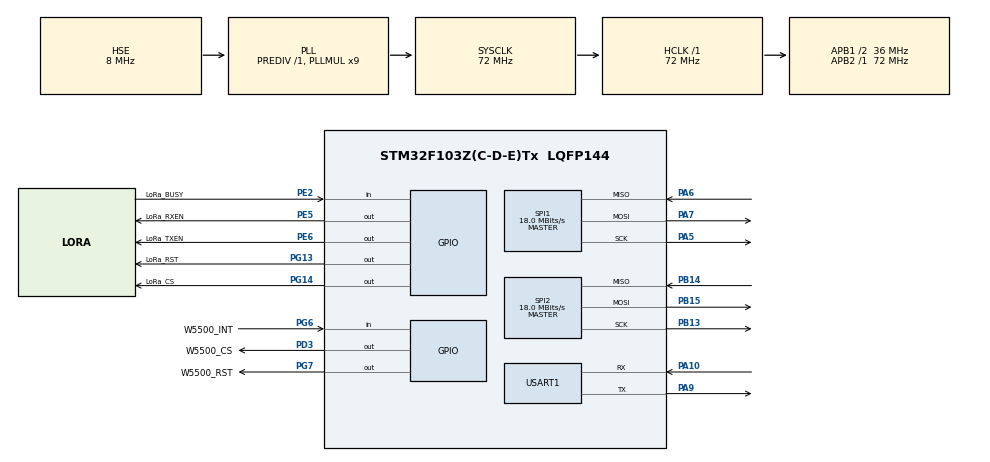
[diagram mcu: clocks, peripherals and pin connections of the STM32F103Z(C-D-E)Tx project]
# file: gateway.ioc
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Mcu.Family=STM32F1
Mcu.Name=STM32F103Z(C-D-E)Tx
Mcu.Package=LQFP144
NVIC.PriorityGroup=NVIC_PRIORITYGROUP_4
OSC_IN.Mode=HSE-External-Oscillator
OSC_IN.Signal=RCC_OSC_IN
OSC_OUT.Mode=HSE-External-Oscillator
OSC_OUT.Signal=RCC_OSC_OUT
PA10.Mode=Asynchronous
PA10.Signal=USART1_RX
PA13.Mode=Serial_Wire
PA13.Signal=SYS_JTMS-SWDIO
PA14.Mode=Serial_Wire
PA14.Signal=SYS_JTCK-SWCLK
PA5.Mode=Full_Duplex_Master
PA5.Signal=SPI1_SCK
PA6.Mode=Full_Duplex_Master
PA6.Signal=SPI1_MISO
PA7.Mode=Full_Duplex_Master
PA7.Signal=SPI1_MOSI
PA9.Mode=Asynchronous
PA9.Signal=USART1_TX
PB13.Mode=Full_Duplex_Master
PB13.Signal=SPI2_SCK
PB14.Mode=Full_Duplex_Master
PB14.Signal=SPI2_MISO
PB15.Mode=Full_Duplex_Master
PB15.Signal=SPI2_MOSI
PC14-OSC32_IN.Mode=LSE-External-Oscillator
PC14-OSC32_IN.Signal=RCC_OSC32_IN
PC15-OSC32_OUT.Mode=LSE-External-Oscillator
PC15-OSC32_OUT.Signal=RCC_OSC32_OUT
PD3.GPIO_Label=W5500_CS
PD3.PinState=GPIO_PIN_SET
PD3.Signal=GPIO_Output
PE2.GPIO_Label=LoRa_BUSY
PE2.Signal=GPIO_Input
PE5.GPIO_Label=LoRa_RXEN
PE5.Signal=GPIO_Output
PE6.GPIO_Label=LoRa_TXEN
PE6.Signal=GPIO_Output
PG13.GPIO_Label=LoRa_RST
PG13.PinState=GPIO_PIN_SET
PG13.Signal=GPIO_Output
PG14.GPIO_Label=LoRa_CS
PG14.PinState=GPIO_PIN_SET
PG14.Signal=GPIO_Output
PG6.GPIO_Label=W5500_INT
PG6.Signal=GPIO_Input
PG7.GPIO_Label=W5500_RST
PG7.PinState=GPIO_PIN_SET
PG7.Signal=GPIO_Output
ProjectManager.HeapSize=0x200
ProjectManager.StackSize=0x400
ProjectManager.TargetToolchain=MDK-ARM V5.32
RCC.AHBFreq_Value=72000000
RCC.APB1CLKDivider=RCC_HCLK_DIV2
RCC.APB1Freq_Value=36000000
RCC.APB1TimFreq_Value=72000000
RCC.APB2Freq_Value=72000000
RCC.APB2TimFreq_Value=72000000
RCC.HCLKFreq_Value=72000000
RCC.PLLMUL=RCC_PLL_MUL9
RCC.PLLSourceVirtual=RCC_PLLSOURCE_HSE
RCC.SYSCLKFreq_VALUE=72000000
RCC.SYSCLKSource=RCC_SYSCLKSOURCE_PLLCLK
RCC.USBFreq_Value=72000000
SPI1.BaudRatePrescaler=SPI_BAUDRATEPRESCALER_4
SPI1.CalculateBaudRate=18.0 MBits/s
SPI1.Direction=SPI_DIRECTION_2LINES
SPI1.Mode=SPI_MODE_MASTER
SPI1.VirtualType=VM_MASTER
SPI2.CalculateBaudRate=18.0 MBits/s
SPI2.Direction=SPI_DIRECTION_2LINES
SPI2.Mode=SPI_MODE_MASTER
SPI2.VirtualType=VM_MASTER
USART1.VirtualMode=VM_ASYNC
board=custom

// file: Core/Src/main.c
/* USER CODE BEGIN Header */
/**
 ******************************************************************************
 * @file           : main.c
 * @brief          : Main program body
 ******************************************************************************
 * @attention
 *
 * Copyright (c) 2026 STMicroelectronics.
 * All rights reserved.
 *
 * This software is licensed under terms that can be found in the LICENSE file
 * in the root directory of this software component.
 * If no LICENSE file comes with this software, it is provided AS-IS.
 *
 ******************************************************************************
 */
/* USER CODE END Header */
#include "main.h"
#include "spi.h"
#include "usart.h"
#include "gpio.h"

/* USER CODE BEGIN Includes */
#include "Com_Debug.h"
#include "Int_Lora.h"
#include "Com_Delay.h"
#include "Int_w5500.h"
/* USER CODE END Includes */

void SystemClock_Config(void);

int main(void)
{

  /* MCU Configuration--------------------------------------------------------*/

  /* Reset of all peripherals, Initializes the Flash interface and the Systick. */
  HAL_Init();

  /* Configure the system clock */
  SystemClock_Config();

  /* Initialize all configured peripherals */
  MX_GPIO_Init();
  MX_USART1_UART_Init();
  MX_SPI1_Init();
  MX_SPI2_Init();
  /* USER CODE BEGIN 2 */
  COM_DEBUG_LN("gateway start");
  // lora初始化
  Int_LoRa_Init();

  // w5500初始化,让w5500加入到局域网下
  Int_W5500_Init();

  /* USER CODE END 2 */

  /* Infinite loop */
  while (1)
  {

    /* USER CODE BEGIN 3 */
    // lora接受数据
    Int_Lora_Receive();
    Com_Delay_Sec(1);
  }
  /* USER CODE END 3 */
}

void SystemClock_Config(void)
{
  RCC_OscInitTypeDef RCC_OscInitStruct = {0};
  RCC_ClkInitTypeDef RCC_ClkInitStruct = {0};

  /** Initializes the RCC Oscillators according to the specified parameters
   * in the RCC_OscInitTypeDef structure.
   */
  RCC_OscInitStruct.OscillatorType = RCC_OSCILLATORTYPE_HSE;
  RCC_OscInitStruct.HSEState = RCC_HSE_ON;
  RCC_OscInitStruct.HSEPredivValue = RCC_HSE_PREDIV_DIV1;
  RCC_OscInitStruct.HSIState = RCC_HSI_ON;
  RCC_OscInitStruct.PLL.PLLState = RCC_PLL_ON;
  RCC_OscInitStruct.PLL.PLLSource = RCC_PLLSOURCE_HSE;
  RCC_OscInitStruct.PLL.PLLMUL = RCC_PLL_MUL9;
  if (HAL_RCC_OscConfig(&RCC_OscInitStruct) != HAL_OK)
  {
    Error_Handler();
  }

  /** Initializes the CPU, AHB and APB buses clocks
   */
  RCC_ClkInitStruct.ClockType = RCC_CLOCKTYPE_HCLK | RCC_CLOCKTYPE_SYSCLK | RCC_CLOCKTYPE_PCLK1 | RCC_CLOCKTYPE_PCLK2;
  RCC_ClkInitStruct.SYSCLKSource = RCC_SYSCLKSOURCE_PLLCLK;
  RCC_ClkInitStruct.AHBCLKDivider = RCC_SYSCLK_DIV1;
  RCC_ClkInitStruct.APB1CLKDivider = RCC_HCLK_DIV2;
  RCC_ClkInitStruct.APB2CLKDivider = RCC_HCLK_DIV1;

  if (HAL_RCC_ClockConfig(&RCC_ClkInitStruct, FLASH_LATENCY_2) != HAL_OK)
  {
    Error_Handler();
  }
}

void Error_Handler(void)
{
  __disable_irq();
  while (1)
  {
  }
}
